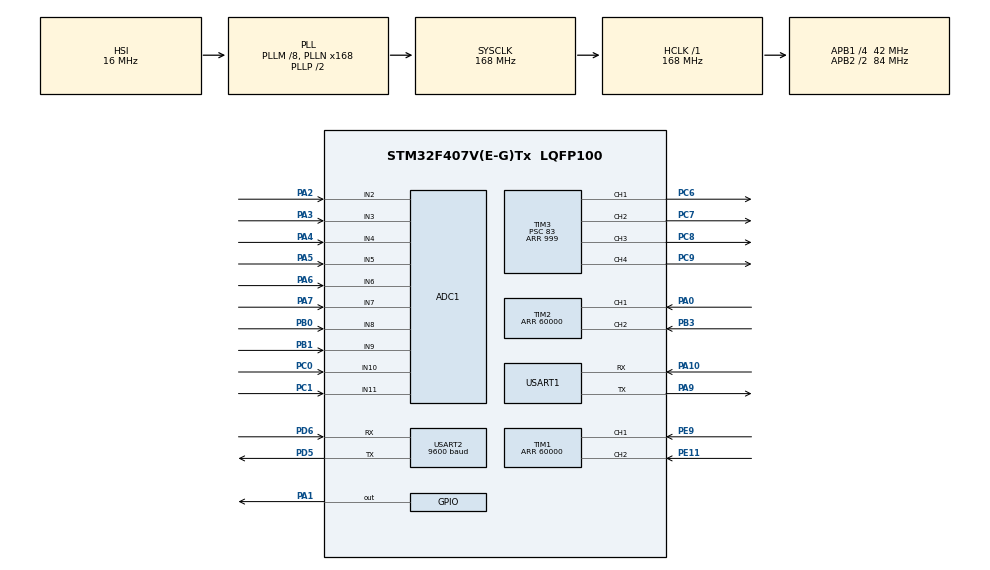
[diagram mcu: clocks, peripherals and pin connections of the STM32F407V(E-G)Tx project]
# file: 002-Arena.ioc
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ADC1.Channel-0\#ChannelRegularConversion=ADC_CHANNEL_2
ADC1.Channel-1\#ChannelRegularConversion=ADC_CHANNEL_3
ADC1.Channel-2\#ChannelRegularConversion=ADC_CHANNEL_4
ADC1.Channel-3\#ChannelRegularConversion=ADC_CHANNEL_5
ADC1.Channel-4\#ChannelRegularConversion=ADC_CHANNEL_6
ADC1.Channel-5\#ChannelRegularConversion=ADC_CHANNEL_7
ADC1.Channel-6\#ChannelRegularConversion=ADC_CHANNEL_8
ADC1.Channel-7\#ChannelRegularConversion=ADC_CHANNEL_9
ADC1.Channel-8\#ChannelRegularConversion=ADC_CHANNEL_10
ADC1.Channel-9\#ChannelRegularConversion=ADC_CHANNEL_11
ADC1.ContinuousConvMode=ENABLE
ADC1.DMAContinuousRequests=ENABLE
ADC1.NbrOfConversion=10
ADC1.NbrOfConversionFlag=1
ADC1.Rank-0\#ChannelRegularConversion=1
ADC1.Rank-1\#ChannelRegularConversion=2
ADC1.Rank-2\#ChannelRegularConversion=3
ADC1.Rank-3\#ChannelRegularConversion=4
ADC1.Rank-4\#ChannelRegularConversion=5
ADC1.Rank-5\#ChannelRegularConversion=6
ADC1.Rank-6\#ChannelRegularConversion=7
ADC1.Rank-7\#ChannelRegularConversion=8
ADC1.Rank-8\#ChannelRegularConversion=9
ADC1.Rank-9\#ChannelRegularConversion=10
ADC1.SamplingTime-0\#ChannelRegularConversion=ADC_SAMPLETIME_3CYCLES
ADC1.SamplingTime-1\#ChannelRegularConversion=ADC_SAMPLETIME_3CYCLES
ADC1.SamplingTime-2\#ChannelRegularConversion=ADC_SAMPLETIME_3CYCLES
ADC1.SamplingTime-3\#ChannelRegularConversion=ADC_SAMPLETIME_3CYCLES
ADC1.SamplingTime-4\#ChannelRegularConversion=ADC_SAMPLETIME_3CYCLES
ADC1.SamplingTime-5\#ChannelRegularConversion=ADC_SAMPLETIME_3CYCLES
ADC1.SamplingTime-6\#ChannelRegularConversion=ADC_SAMPLETIME_3CYCLES
ADC1.SamplingTime-7\#ChannelRegularConversion=ADC_SAMPLETIME_3CYCLES
ADC1.SamplingTime-8\#ChannelRegularConversion=ADC_SAMPLETIME_3CYCLES
ADC1.SamplingTime-9\#ChannelRegularConversion=ADC_SAMPLETIME_3CYCLES
ADC1.ScanConvMode=ENABLE
ADC1.master=1
Dma.ADC1.0.Direction=DMA_PERIPH_TO_MEMORY
Dma.ADC1.0.FIFOMode=DMA_FIFOMODE_DISABLE
Dma.ADC1.0.Instance=DMA2_Stream0
Dma.ADC1.0.MemDataAlignment=DMA_MDATAALIGN_WORD
Dma.ADC1.0.MemInc=DMA_MINC_ENABLE
Dma.ADC1.0.Mode=DMA_CIRCULAR
Dma.ADC1.0.PeriphDataAlignment=DMA_PDATAALIGN_WORD
Dma.ADC1.0.PeriphInc=DMA_PINC_DISABLE
Dma.ADC1.0.Priority=DMA_PRIORITY_LOW
Dma.Request0=ADC1
Dma.Request1=USART1_RX
Dma.Request2=USART1_TX
Dma.Request3=USART2_RX
Dma.Request4=USART2_TX
Dma.USART1_RX.1.Direction=DMA_PERIPH_TO_MEMORY
Dma.USART1_RX.1.FIFOMode=DMA_FIFOMODE_DISABLE
Dma.USART1_RX.1.Instance=DMA2_Stream2
Dma.USART1_RX.1.MemDataAlignment=DMA_MDATAALIGN_BYTE
Dma.USART1_RX.1.MemInc=DMA_MINC_ENABLE
Dma.USART1_RX.1.Mode=DMA_CIRCULAR
Dma.USART1_RX.1.PeriphDataAlignment=DMA_PDATAALIGN_BYTE
Dma.USART1_RX.1.PeriphInc=DMA_PINC_DISABLE
Dma.USART1_RX.1.Priority=DMA_PRIORITY_LOW
Dma.USART1_TX.2.Direction=DMA_MEMORY_TO_PERIPH
Dma.USART1_TX.2.FIFOMode=DMA_FIFOMODE_DISABLE
Dma.USART1_TX.2.Instance=DMA2_Stream7
Dma.USART1_TX.2.MemDataAlignment=DMA_MDATAALIGN_BYTE
Dma.USART1_TX.2.MemInc=DMA_MINC_ENABLE
Dma.USART1_TX.2.Mode=DMA_NORMAL
Dma.USART1_TX.2.PeriphDataAlignment=DMA_PDATAALIGN_BYTE
Dma.USART1_TX.2.PeriphInc=DMA_PINC_DISABLE
Dma.USART1_TX.2.Priority=DMA_PRIORITY_LOW
Dma.USART2_RX.3.Direction=DMA_PERIPH_TO_MEMORY
Dma.USART2_RX.3.FIFOMode=DMA_FIFOMODE_DISABLE
Dma.USART2_RX.3.Instance=DMA1_Stream5
Dma.USART2_RX.3.MemDataAlignment=DMA_MDATAALIGN_BYTE
Dma.USART2_RX.3.MemInc=DMA_MINC_ENABLE
Dma.USART2_RX.3.Mode=DMA_CIRCULAR
Dma.USART2_RX.3.PeriphDataAlignment=DMA_PDATAALIGN_BYTE
Dma.USART2_RX.3.PeriphInc=DMA_PINC_DISABLE
Dma.USART2_RX.3.Priority=DMA_PRIORITY_LOW
Dma.USART2_TX.4.Direction=DMA_MEMORY_TO_PERIPH
Dma.USART2_TX.4.FIFOMode=DMA_FIFOMODE_DISABLE
Dma.USART2_TX.4.Instance=DMA1_Stream6
Dma.USART2_TX.4.MemDataAlignment=DMA_MDATAALIGN_BYTE
Dma.USART2_TX.4.MemInc=DMA_MINC_ENABLE
Dma.USART2_TX.4.Mode=DMA_NORMAL
Dma.USART2_TX.4.PeriphDataAlignment=DMA_PDATAALIGN_BYTE
Dma.USART2_TX.4.PeriphInc=DMA_PINC_DISABLE
Dma.USART2_TX.4.Priority=DMA_PRIORITY_LOW
FREERTOS.Tasks01=defaultTask,0,128,StartDefaultTask,Default,NULL,Dynamic,NULL,NULL;OLED_task,0,128,OLED_function,Default,NULL,Dynamic,NULL,NULL;Encode_Task,1,128,Encode_function,Default,NULL,Dynamic,NULL,NULL;motor_Task,1,128,motor_function,Default,NULL,Dynamic,NULL,NULL
FREERTOS.configUSE_COUNTING_SEMAPHORES=0
Mcu.Family=STM32F4
Mcu.Name=STM32F407V(E-G)Tx
Mcu.Package=LQFP100
NVIC.ADC_IRQn=true\:5\:0\:false\:false\:true\:true\:true\:true
NVIC.DMA1_Stream5_IRQn=true\:5\:0\:false\:false\:true\:true\:false\:true
NVIC.DMA1_Stream6_IRQn=true\:5\:0\:false\:false\:true\:true\:false\:true
NVIC.DMA2_Stream0_IRQn=true\:5\:0\:false\:false\:true\:true\:false\:true
NVIC.DMA2_Stream2_IRQn=true\:5\:0\:false\:false\:true\:true\:false\:true
NVIC.DMA2_Stream7_IRQn=true\:5\:0\:false\:false\:true\:true\:false\:true
NVIC.PriorityGroup=NVIC_PRIORITYGROUP_4
NVIC.TIM8_TRG_COM_TIM14_IRQn=true\:0\:0\:false\:false\:true\:false\:false\:true
NVIC.TimeBase=TIM8_TRG_COM_TIM14_IRQn
NVIC.TimeBaseIP=TIM14
NVIC.USART1_IRQn=true\:5\:0\:false\:false\:true\:true\:true\:true
NVIC.USART2_IRQn=true\:5\:0\:false\:false\:true\:true\:true\:true
PA0-WKUP.GPIO_PuPd=GPIO_PULLUP
PA0-WKUP.Signal=S_TIM2_CH1_ETR
PA1.Signal=GPIO_Output
PA10.Mode=Asynchronous
PA10.Signal=USART1_RX
PA13.Mode=Serial_Wire
PA13.Signal=SYS_JTMS-SWDIO
PA14.Mode=Serial_Wire
PA14.Signal=SYS_JTCK-SWCLK
PA2.Signal=ADCx_IN2
PA3.Signal=ADCx_IN3
PA4.Signal=ADCx_IN4
PA5.Signal=ADCx_IN5
PA6.Signal=ADCx_IN6
PA7.Signal=ADCx_IN7
PA9.Mode=Asynchronous
PA9.Signal=USART1_TX
PB0.Signal=ADCx_IN8
PB1.Signal=ADCx_IN9
PB3.GPIO_PuPd=GPIO_PULLUP
PB3.Signal=S_TIM2_CH2
PC0.Signal=ADCx_IN10
PC1.Signal=ADCx_IN11
PC6.Signal=S_TIM3_CH1
PC7.Signal=S_TIM3_CH2
PC8.Signal=S_TIM3_CH3
PC9.Signal=S_TIM3_CH4
PD5.Mode=Asynchronous
PD5.Signal=USART2_TX
PD6.Mode=Asynchronous
PD6.Signal=USART2_RX
PE11.GPIO_PuPd=GPIO_PULLUP
PE11.Signal=S_TIM1_CH2
PE9.GPIO_PuPd=GPIO_PULLUP
PE9.Signal=S_TIM1_CH1
PH0-OSC_IN.Mode=HSE-External-Oscillator
PH0-OSC_IN.Signal=RCC_OSC_IN
PH1-OSC_OUT.Mode=HSE-External-Oscillator
PH1-OSC_OUT.Signal=RCC_OSC_OUT
ProjectManager.HeapSize=0x200
ProjectManager.StackSize=0x400
ProjectManager.TargetToolchain=SW4STM32
RCC.48MHZClocksFreq_Value=84000000
RCC.AHBFreq_Value=168000000
RCC.APB1CLKDivider=RCC_HCLK_DIV4
RCC.APB1Freq_Value=42000000
RCC.APB1TimFreq_Value=84000000
RCC.APB2CLKDivider=RCC_HCLK_DIV2
RCC.APB2Freq_Value=84000000
RCC.APB2TimFreq_Value=168000000
RCC.CortexFreq_Value=168000000
RCC.HCLKFreq_Value=168000000
RCC.HSE_VALUE=25000000
RCC.HSI_VALUE=16000000
RCC.LSE_VALUE=32768
RCC.PLLM=8
RCC.PLLN=168
RCC.SYSCLKFreq_VALUE=168000000
RCC.SYSCLKSource=RCC_SYSCLKSOURCE_PLLCLK
RCC.VCOOutputFreq_Value=336000000
SH.ADCx_IN10.0=ADC1_IN10,IN10
SH.ADCx_IN11.0=ADC1_IN11,IN11
SH.ADCx_IN2.0=ADC1_IN2,IN2
SH.ADCx_IN3.0=ADC1_IN3,IN3
SH.ADCx_IN4.0=ADC1_IN4,IN4
SH.ADCx_IN5.0=ADC1_IN5,IN5
SH.ADCx_IN6.0=ADC1_IN6,IN6
SH.ADCx_IN7.0=ADC1_IN7,IN7
SH.ADCx_IN8.0=ADC1_IN8,IN8
SH.ADCx_IN9.0=ADC1_IN9,IN9
SH.S_TIM1_CH1.0=TIM1_CH1,Encoder_Interface
SH.S_TIM1_CH2.0=TIM1_CH2,Encoder_Interface
SH.S_TIM2_CH1_ETR.0=TIM2_CH1,Encoder_Interface
SH.S_TIM2_CH2.0=TIM2_CH2,Encoder_Interface
SH.S_TIM3_CH1.0=TIM3_CH1,PWM Generation1 CH1
SH.S_TIM3_CH2.0=TIM3_CH2,PWM Generation2 CH2
SH.S_TIM3_CH3.0=TIM3_CH3,PWM Generation3 CH3
SH.S_TIM3_CH4.0=TIM3_CH4,PWM Generation4 CH4
TIM1.EncoderMode=TIM_ENCODERMODE_TI1
TIM1.Period=60000
TIM2.Period=60000
TIM3.Channel-PWM\ Generation1\ CH1=TIM_CHANNEL_1
TIM3.Channel-PWM\ Generation2\ CH2=TIM_CHANNEL_2
TIM3.Channel-PWM\ Generation3\ CH3=TIM_CHANNEL_3
TIM3.Channel-PWM\ Generation4\ CH4=TIM_CHANNEL_4
TIM3.Period=999
TIM3.Prescaler=83
USART1.VirtualMode=VM_ASYNC
USART2.BaudRate=9600
USART2.VirtualMode=VM_ASYNC
VP_FREERTOS_VS_CMSIS_V1.Mode=CMSIS_V1
VP_SYS_VS_tim14.Mode=TIM14
board=custom

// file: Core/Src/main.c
/* USER CODE BEGIN Header */
/**
  ******************************************************************************
  * @file           : main.c
  * @brief          : Main program body
  ******************************************************************************
  * @attention
  *
  * <h2><center>&copy; Copyright (c) 2021 STMicroelectronics.
  * All rights reserved.</center></h2>
  *
  * This software component is licensed by ST under Ultimate Liberty license
  * SLA0044, the "License"; You may not use this file except in compliance with
  * the License. You may obtain a copy of the License at:
  *                             www.st.com/SLA0044
  *
  ******************************************************************************
  */
/* USER CODE END Header */
#include "main.h"
#include "cmsis_os.h"

/* USER CODE BEGIN Includes */

#include "macro.h"

/* USER CODE END Includes */

ADC_HandleTypeDef hadc1;
DMA_HandleTypeDef hdma_adc1;

TIM_HandleTypeDef htim1;
TIM_HandleTypeDef htim2;
TIM_HandleTypeDef htim3;

UART_HandleTypeDef huart1;
UART_HandleTypeDef huart2;
DMA_HandleTypeDef hdma_usart1_rx;
DMA_HandleTypeDef hdma_usart1_tx;
DMA_HandleTypeDef hdma_usart2_rx;
DMA_HandleTypeDef hdma_usart2_tx;

osThreadId defaultTaskHandle;
osThreadId OLED_taskHandle;
osThreadId Encode_TaskHandle;
osThreadId motor_TaskHandle;

void SystemClock_Config(void);

static void MX_GPIO_Init(void);

static void MX_DMA_Init(void);

static void MX_ADC1_Init(void);

static void MX_TIM1_Init(void);

static void MX_TIM2_Init(void);

static void MX_TIM3_Init(void);

static void MX_USART1_UART_Init(void);

static void MX_USART2_UART_Init(void);

void StartDefaultTask(void const *argument);

void OLED_function(void const *argument);

void Encode_function(void const *argument);

void motor_function(void const *argument);

int main(void) {

    /* MCU Configuration--------------------------------------------------------*/

    /* Reset of all peripherals, Initializes the Flash interface and the Systick. */
    HAL_Init();

    /* Configure the system clock */
    SystemClock_Config();

    /* Initialize all configured peripherals */
    MX_GPIO_Init();
    MX_DMA_Init();
    MX_ADC1_Init();
    MX_TIM1_Init();
    MX_TIM2_Init();
    MX_TIM3_Init();
    MX_USART1_UART_Init();
    MX_USART2_UART_Init();
    /* USER CODE BEGIN 2 */

    hardware_Init();

    ParamInit();

    /* USER CODE END 2 */

    /* Create the thread(s) */
    /* definition and creation of defaultTask */
    osThreadDef(defaultTask, StartDefaultTask, osPriorityNormal, 0, 128);
    defaultTaskHandle = osThreadCreate(osThread(defaultTask), NULL);

    /* definition and creation of OLED_task */
    osThreadDef(OLED_task, OLED_function, osPriorityNormal, 0, 128);
    OLED_taskHandle = osThreadCreate(osThread(OLED_task), NULL);

    /* definition and creation of Encode_Task */
    osThreadDef(Encode_Task, Encode_function, osPriorityAboveNormal, 0, 128);
    Encode_TaskHandle = osThreadCreate(osThread(Encode_Task), NULL);

    /* definition and creation of motor_Task */
    osThreadDef(motor_Task, motor_function, osPriorityAboveNormal, 0, 128);
    motor_TaskHandle = osThreadCreate(osThread(motor_Task), NULL);

    /* Start scheduler */
    osKernelStart();

    /* We should never get here as control is now taken by the scheduler */
    /* Infinite loop */
    while (1) {

    }
}

void SystemClock_Config(void) {
    RCC_OscInitTypeDef RCC_OscInitStruct = { 0 };
    RCC_ClkInitTypeDef RCC_ClkInitStruct = { 0 };

    /** Configure the main internal regulator output voltage
    */
    __HAL_RCC_PWR_CLK_ENABLE();
    __HAL_PWR_VOLTAGESCALING_CONFIG(PWR_REGULATOR_VOLTAGE_SCALE1);
    /** Initializes the RCC Oscillators according to the specified parameters
    * in the RCC_OscInitTypeDef structure.
    */
    RCC_OscInitStruct.OscillatorType = RCC_OSCILLATORTYPE_HSI;
    RCC_OscInitStruct.HSIState = RCC_HSI_ON;
    RCC_OscInitStruct.HSICalibrationValue = RCC_HSICALIBRATION_DEFAULT;
    RCC_OscInitStruct.PLL.PLLState = RCC_PLL_ON;
    RCC_OscInitStruct.PLL.PLLSource = RCC_PLLSOURCE_HSI;
    RCC_OscInitStruct.PLL.PLLM = 8;
    RCC_OscInitStruct.PLL.PLLN = 168;
    RCC_OscInitStruct.PLL.PLLP = RCC_PLLP_DIV2;
    RCC_OscInitStruct.PLL.PLLQ = 4;
    if (HAL_RCC_OscConfig(&RCC_OscInitStruct) != HAL_OK) {
        Error_Handler();
    }
    /** Initializes the CPU, AHB and APB buses clocks
    */
    RCC_ClkInitStruct.ClockType = RCC_CLOCKTYPE_HCLK | RCC_CLOCKTYPE_SYSCLK
                                  | RCC_CLOCKTYPE_PCLK1 | RCC_CLOCKTYPE_PCLK2;
    RCC_ClkInitStruct.SYSCLKSource = RCC_SYSCLKSOURCE_PLLCLK;
    RCC_ClkInitStruct.AHBCLKDivider = RCC_SYSCLK_DIV1;
    RCC_ClkInitStruct.APB1CLKDivider = RCC_HCLK_DIV4;
    RCC_ClkInitStruct.APB2CLKDivider = RCC_HCLK_DIV2;

    if (HAL_RCC_ClockConfig(&RCC_ClkInitStruct, FLASH_LATENCY_5) != HAL_OK) {
        Error_Handler();
    }
}

static void MX_ADC1_Init(void) {

    ADC_ChannelConfTypeDef sConfig = { 0 };

    /** Configure the global features of the ADC (Clock, Resolution, Data Alignment and number of conversion)
    */
    hadc1.Instance = ADC1;
    hadc1.Init.ClockPrescaler = ADC_CLOCK_SYNC_PCLK_DIV4;
    hadc1.Init.Resolution = ADC_RESOLUTION_12B;
    hadc1.Init.ScanConvMode = ENABLE;
    hadc1.Init.ContinuousConvMode = ENABLE;
    hadc1.Init.DiscontinuousConvMode = DISABLE;
    hadc1.Init.ExternalTrigConvEdge = ADC_EXTERNALTRIGCONVEDGE_NONE;
    hadc1.Init.ExternalTrigConv = ADC_SOFTWARE_START;
    hadc1.Init.DataAlign = ADC_DATAALIGN_RIGHT;
    hadc1.Init.NbrOfConversion = 10;
    hadc1.Init.DMAContinuousRequests = ENABLE;
    hadc1.Init.EOCSelection = ADC_EOC_SINGLE_CONV;
    if (HAL_ADC_Init(&hadc1) != HAL_OK) {
        Error_Handler();
    }
    /** Configure for the selected ADC regular channel its corresponding rank in the sequencer and its sample time.
    */
    sConfig.Channel = ADC_CHANNEL_2;
    sConfig.Rank = 1;
    sConfig.SamplingTime = ADC_SAMPLETIME_3CYCLES;
    if (HAL_ADC_ConfigChannel(&hadc1, &sConfig) != HAL_OK) {
        Error_Handler();
    }
    /** Configure for the selected ADC regular channel its corresponding rank in the sequencer and its sample time.
    */
    sConfig.Channel = ADC_CHANNEL_3;
    sConfig.Rank = 2;
    if (HAL_ADC_ConfigChannel(&hadc1, &sConfig) != HAL_OK) {
        Error_Handler();
    }
    /** Configure for the selected ADC regular channel its corresponding rank in the sequencer and its sample time.
    */
    sConfig.Channel = ADC_CHANNEL_4;
    sConfig.Rank = 3;
    if (HAL_ADC_ConfigChannel(&hadc1, &sConfig) != HAL_OK) {
        Error_Handler();
    }
    /** Configure for the selected ADC regular channel its corresponding rank in the sequencer and its sample time.
    */
    sConfig.Channel = ADC_CHANNEL_5;
    sConfig.Rank = 4;
    if (HAL_ADC_ConfigChannel(&hadc1, &sConfig) != HAL_OK) {
        Error_Handler();
    }
    /** Configure for the selected ADC regular channel its corresponding rank in the sequencer and its sample time.
    */
    sConfig.Channel = ADC_CHANNEL_6;
    sConfig.Rank = 5;
    if (HAL_ADC_ConfigChannel(&hadc1, &sConfig) != HAL_OK) {
        Error_Handler();
    }
    /** Configure for the selected ADC regular channel its corresponding rank in the sequencer and its sample time.
    */
    sConfig.Channel = ADC_CHANNEL_7;
    sConfig.Rank = 6;
    if (HAL_ADC_ConfigChannel(&hadc1, &sConfig) != HAL_OK) {
        Error_Handler();
    }
    /** Configure for the selected ADC regular channel its corresponding rank in the sequencer and its sample time.
    */
    sConfig.Channel = ADC_CHANNEL_8;
    sConfig.Rank = 7;
    if (HAL_ADC_ConfigChannel(&hadc1, &sConfig) != HAL_OK) {
        Error_Handler();
    }
    /** Configure for the selected ADC regular channel its corresponding rank in the sequencer and its sample time.
    */
    sConfig.Channel = ADC_CHANNEL_9;
    sConfig.Rank = 8;
    if (HAL_ADC_ConfigChannel(&hadc1, &sConfig) != HAL_OK) {
        Error_Handler();
    }
    /** Configure for the selected ADC regular channel its corresponding rank in the sequencer and its sample time.
    */
    sConfig.Channel = ADC_CHANNEL_10;
    sConfig.Rank = 9;
    if (HAL_ADC_ConfigChannel(&hadc1, &sConfig) != HAL_OK) {
        Error_Handler();
    }
    /** Configure for the selected ADC regular channel its corresponding rank in the sequencer and its sample time.
    */
    sConfig.Channel = ADC_CHANNEL_11;
    sConfig.Rank = 10;
    if (HAL_ADC_ConfigChannel(&hadc1, &sConfig) != HAL_OK) {
        Error_Handler();
    }

}

static void MX_TIM1_Init(void) {

    TIM_Encoder_InitTypeDef sConfig = { 0 };
    TIM_MasterConfigTypeDef sMasterConfig = { 0 };

    htim1.Instance = TIM1;
    htim1.Init.Prescaler = 0;
    htim1.Init.CounterMode = TIM_COUNTERMODE_UP;
    htim1.Init.Period = 60000;
    htim1.Init.ClockDivision = TIM_CLOCKDIVISION_DIV1;
    htim1.Init.RepetitionCounter = 0;
    htim1.Init.AutoReloadPreload = TIM_AUTORELOAD_PRELOAD_DISABLE;
    sConfig.EncoderMode = TIM_ENCODERMODE_TI1;
    sConfig.IC1Polarity = TIM_ICPOLARITY_RISING;
    sConfig.IC1Selection = TIM_ICSELECTION_DIRECTTI;
    sConfig.IC1Prescaler = TIM_ICPSC_DIV1;
    sConfig.IC1Filter = 0;
    sConfig.IC2Polarity = TIM_ICPOLARITY_RISING;
    sConfig.IC2Selection = TIM_ICSELECTION_DIRECTTI;
    sConfig.IC2Prescaler = TIM_ICPSC_DIV1;
    sConfig.IC2Filter = 0;
    if (HAL_TIM_Encoder_Init(&htim1, &sConfig) != HAL_OK) {
        Error_Handler();
    }
    sMasterConfig.MasterOutputTrigger = TIM_TRGO_RESET;
    sMasterConfig.MasterSlaveMode = TIM_MASTERSLAVEMODE_DISABLE;
    if (HAL_TIMEx_MasterConfigSynchronization(&htim1, &sMasterConfig) != HAL_OK) {
        Error_Handler();
    }

}

static void MX_TIM2_Init(void) {

    TIM_Encoder_InitTypeDef sConfig = { 0 };
    TIM_MasterConfigTypeDef sMasterConfig = { 0 };

    htim2.Instance = TIM2;
    htim2.Init.Prescaler = 0;
    htim2.Init.CounterMode = TIM_COUNTERMODE_UP;
    htim2.Init.Period = 60000;
    htim2.Init.ClockDivision = TIM_CLOCKDIVISION_DIV1;
    htim2.Init.AutoReloadPreload = TIM_AUTORELOAD_PRELOAD_DISABLE;
    sConfig.EncoderMode = TIM_ENCODERMODE_TI1;
    sConfig.IC1Polarity = TIM_ICPOLARITY_RISING;
    sConfig.IC1Selection = TIM_ICSELECTION_DIRECTTI;
    sConfig.IC1Prescaler = TIM_ICPSC_DIV1;
    sConfig.IC1Filter = 0;
    sConfig.IC2Polarity = TIM_ICPOLARITY_RISING;
    sConfig.IC2Selection = TIM_ICSELECTION_DIRECTTI;
    sConfig.IC2Prescaler = TIM_ICPSC_DIV1;
    sConfig.IC2Filter = 0;
    if (HAL_TIM_Encoder_Init(&htim2, &sConfig) != HAL_OK) {
        Error_Handler();
    }
    sMasterConfig.MasterOutputTrigger = TIM_TRGO_RESET;
    sMasterConfig.MasterSlaveMode = TIM_MASTERSLAVEMODE_DISABLE;
    if (HAL_TIMEx_MasterConfigSynchronization(&htim2, &sMasterConfig) != HAL_OK) {
        Error_Handler();
    }

}

static void MX_TIM3_Init(void) {

    TIM_MasterConfigTypeDef sMasterConfig = { 0 };
    TIM_OC_InitTypeDef sConfigOC = { 0 };

    htim3.Instance = TIM3;
    htim3.Init.Prescaler = 83;
    htim3.Init.CounterMode = TIM_COUNTERMODE_UP;
    htim3.Init.Period = 999;
    htim3.Init.ClockDivision = TIM_CLOCKDIVISION_DIV1;
    htim3.Init.AutoReloadPreload = TIM_AUTORELOAD_PRELOAD_DISABLE;
    if (HAL_TIM_PWM_Init(&htim3) != HAL_OK) {
        Error_Handler();
    }
    sMasterConfig.MasterOutputTrigger = TIM_TRGO_RESET;
    sMasterConfig.MasterSlaveMode = TIM_MASTERSLAVEMODE_DISABLE;
    if (HAL_TIMEx_MasterConfigSynchronization(&htim3, &sMasterConfig) != HAL_OK) {
        Error_Handler();
    }
    sConfigOC.OCMode = TIM_OCMODE_PWM1;
    sConfigOC.Pulse = 0;
    sConfigOC.OCPolarity = TIM_OCPOLARITY_HIGH;
    sConfigOC.OCFastMode = TIM_OCFAST_DISABLE;
    if (HAL_TIM_PWM_ConfigChannel(&htim3, &sConfigOC, TIM_CHANNEL_1) != HAL_OK) {
        Error_Handler();
    }
    if (HAL_TIM_PWM_ConfigChannel(&htim3, &sConfigOC, TIM_CHANNEL_2) != HAL_OK) {
        Error_Handler();
    }
    if (HAL_TIM_PWM_ConfigChannel(&htim3, &sConfigOC, TIM_CHANNEL_3) != HAL_OK) {
        Error_Handler();
    }
    if (HAL_TIM_PWM_ConfigChannel(&htim3, &sConfigOC, TIM_CHANNEL_4) != HAL_OK) {
        Error_Handler();
    }
    HAL_TIM_MspPostInit(&htim3);

}

static void MX_USART1_UART_Init(void) {

    huart1.Instance = USART1;
    huart1.Init.BaudRate = 115200;
    huart1.Init.WordLength = UART_WORDLENGTH_8B;
    huart1.Init.StopBits = UART_STOPBITS_1;
    huart1.Init.Parity = UART_PARITY_NONE;
    huart1.Init.Mode = UART_MODE_TX_RX;
    huart1.Init.HwFlowCtl = UART_HWCONTROL_NONE;
    huart1.Init.OverSampling = UART_OVERSAMPLING_16;
    if (HAL_UART_Init(&huart1) != HAL_OK) {
        Error_Handler();
    }

}

static void MX_USART2_UART_Init(void) {

    huart2.Instance = USART2;
    huart2.Init.BaudRate = 9600;
    huart2.Init.WordLength = UART_WORDLENGTH_8B;
    huart2.Init.StopBits = UART_STOPBITS_1;
    huart2.Init.Parity = UART_PARITY_NONE;
    huart2.Init.Mode = UART_MODE_TX_RX;
    huart2.Init.HwFlowCtl = UART_HWCONTROL_NONE;
    huart2.Init.OverSampling = UART_OVERSAMPLING_16;
    if (HAL_UART_Init(&huart2) != HAL_OK) {
        Error_Handler();
    }

}

static void MX_DMA_Init(void) {

    /* DMA controller clock enable */
    __HAL_RCC_DMA2_CLK_ENABLE();
    __HAL_RCC_DMA1_CLK_ENABLE();

    /* DMA interrupt init */
    /* DMA1_Stream5_IRQn interrupt configuration */
    HAL_NVIC_SetPriority(DMA1_Stream5_IRQn, 5, 0);
    HAL_NVIC_EnableIRQ(DMA1_Stream5_IRQn);
    /* DMA1_Stream6_IRQn interrupt configuration */
    HAL_NVIC_SetPriority(DMA1_Stream6_IRQn, 5, 0);
    HAL_NVIC_EnableIRQ(DMA1_Stream6_IRQn);
    /* DMA2_Stream0_IRQn interrupt configuration */
    HAL_NVIC_SetPriority(DMA2_Stream0_IRQn, 5, 0);
    HAL_NVIC_EnableIRQ(DMA2_Stream0_IRQn);
    /* DMA2_Stream2_IRQn interrupt configuration */
    HAL_NVIC_SetPriority(DMA2_Stream2_IRQn, 5, 0);
    HAL_NVIC_EnableIRQ(DMA2_Stream2_IRQn);
    /* DMA2_Stream7_IRQn interrupt configuration */
    HAL_NVIC_SetPriority(DMA2_Stream7_IRQn, 5, 0);
    HAL_NVIC_EnableIRQ(DMA2_Stream7_IRQn);

}

static void MX_GPIO_Init(void) {
    GPIO_InitTypeDef GPIO_InitStruct = { 0 };

    /* GPIO Ports Clock Enable */
    __HAL_RCC_GPIOH_CLK_ENABLE();
    __HAL_RCC_GPIOC_CLK_ENABLE();
    __HAL_RCC_GPIOA_CLK_ENABLE();
    __HAL_RCC_GPIOB_CLK_ENABLE();
    __HAL_RCC_GPIOE_CLK_ENABLE();
    __HAL_RCC_GPIOD_CLK_ENABLE();

    /*Configure GPIO pin Output Level */
    HAL_GPIO_WritePin(GPIOA, GPIO_PIN_1, GPIO_PIN_RESET);

    /*Configure GPIO pin : PA1 */
    GPIO_InitStruct.Pin = GPIO_PIN_1;
    GPIO_InitStruct.Mode = GPIO_MODE_OUTPUT_PP;
    GPIO_InitStruct.Pull = GPIO_NOPULL;
    GPIO_InitStruct.Speed = GPIO_SPEED_FREQ_LOW;
    HAL_GPIO_Init(GPIOA, &GPIO_InitStruct);

}

void StartDefaultTask(void const *argument) {
    for (;;) {
        osDelay(1);
    }
}

void OLED_function(void const *argument) {
    /* USER CODE BEGIN OLED_function */
    /* Infinite loop */
    for (;;) {
        OLED_Show();
        osDelay(1);
    }
    /* USER CODE END OLED_function */
}

void Encode_function(void const *argument) {
    for (;;) {
        osDelay(1);
    }
}

void motor_function(void const *argument) {
    for (;;) {
        osDelay(1);
    }
}

void HAL_TIM_PeriodElapsedCallback(TIM_HandleTypeDef *htim) {
    if (htim->Instance == TIM14) {
        HAL_IncTick();
    }
}

void Error_Handler(void) {
    __disable_irq();
    while (1) {
    }
}

/************************ (C) COPYRIGHT STMicroelectronics *****END OF FILE****/
